VERSION ""

NS_ :

BS_:

BU_: BMS Third_Party_Device

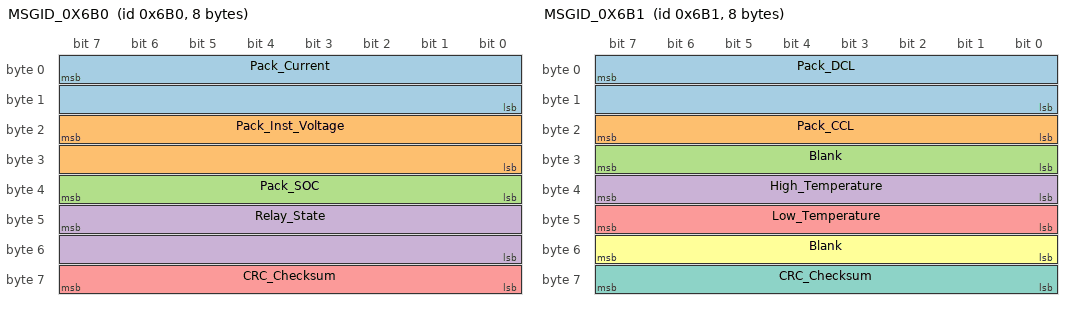
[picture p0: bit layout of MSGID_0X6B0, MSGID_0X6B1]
BO_ 1712 MSGID_0X6B0: 8 BMS
 SG_ Pack_Current : 7|16@0+ (0.1,0) [0|0] "Amps"  Third_Party_Device
 SG_ Pack_Inst_Voltage : 23|16@0+ (0.1,0) [0|0] "Volts"  Third_Party_Device
 SG_ Pack_SOC : 39|8@0+ (0.5,0) [0|0] "Percent"  Third_Party_Device
 SG_ Relay_State : 47|16@0+ (1.0,0) [0|0] ""  Third_Party_Device
 SG_ CRC_Checksum : 63|8@0+ (1.0,1720) [0|0] ""  Third_Party_Device

BO_ 1713 MSGID_0X6B1: 8 BMS
 SG_ Pack_DCL : 7|16@0+ (1.0,0) [0|0] "Amps"  Third_Party_Device
 SG_ Pack_CCL : 23|8@0+ (1.0,0) [0|0] "Amps"  Third_Party_Device
 SG_ Blank : 31|8@0+ (1.0,0) [0|0] ""  Third_Party_Device
 SG_ High_Temperature : 39|8@0+ (1.0,0) [0|0] "Celsius"  Third_Party_Device
 SG_ Low_Temperature : 47|8@0+ (1.0,0) [0|0] "Celsius"  Third_Party_Device
 SG_ Blank : 55|8@0+ (1.0,0) [0|0] ""  Third_Party_Device
 SG_ CRC_Checksum : 63|8@0+ (1.0,1721) [0|0] ""  Third_Party_Device

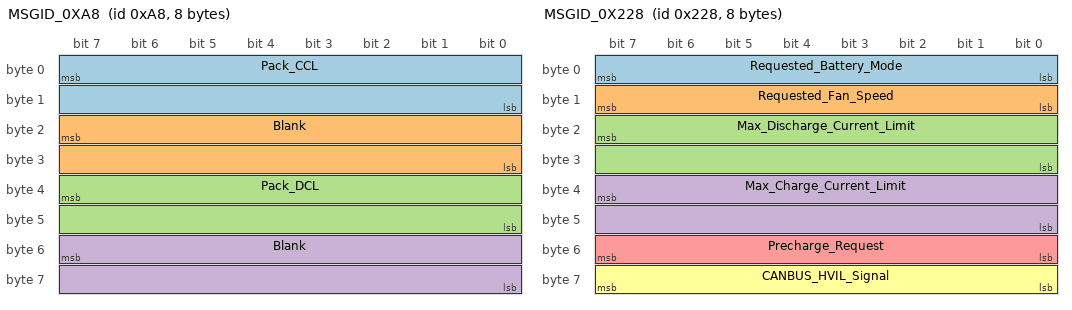
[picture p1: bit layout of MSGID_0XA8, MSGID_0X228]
BO_ 168 MSGID_0XA8: 8 BMS
 SG_ Pack_CCL : 7|16@0+ (0.1,0) [0|0] "Amps"  Third_Party_Device
 SG_ Blank : 23|16@0+ (1.0,0) [0|0] ""  Third_Party_Device
 SG_ Pack_DCL : 39|16@0+ (1.0,0) [0|0] "Amps"  Third_Party_Device
 SG_ Blank : 55|16@0+ (1.0,0) [0|0] ""  Third_Party_Device

BO_ 552 MSGID_0X228: 8 Third_Party_Device
 SG_ Requested_Battery_Mode : 7|8@0+ (1.0,0) [0|0] "#"  BMS
 SG_ Requested_Fan_Speed : 15|8@0+ (1.0,0) [0|0] "#"  BMS
 SG_ Max_Discharge_Current_Limit : 23|16@0+ (1.0,0) [0|0] "Amps"  BMS
 SG_ Max_Charge_Current_Limit : 39|16@0+ (1.0,0) [0|0] "Amps"  BMS
 SG_ Precharge_Request : 55|8@0+ (1.0,0) [0|0] "ON/OFF"  BMS
 SG_ CANBUS_HVIL_Signal : 63|8@0+ (1.0,0) [0|0] ""  BMS

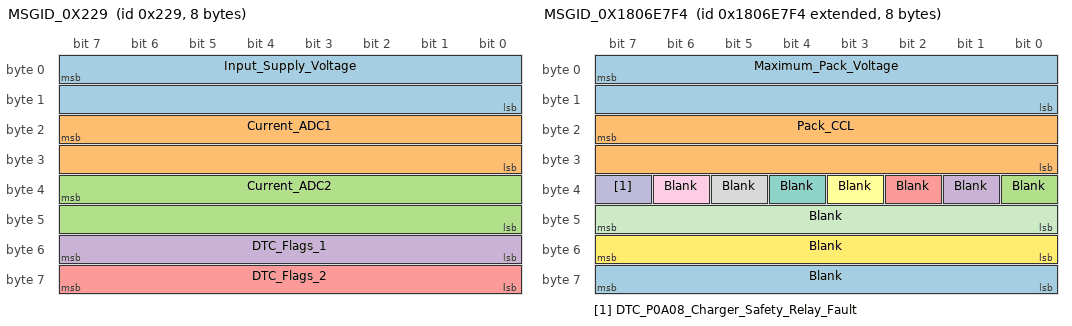
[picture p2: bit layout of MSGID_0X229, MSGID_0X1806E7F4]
BO_ 553 MSGID_0X229: 8 BMS
 SG_ Input_Supply_Voltage : 7|16@0+ (1.0,0) [0|0] "Volts"  Third_Party_Device
 SG_ Current_ADC1 : 23|16@0+ (1.0,0) [0|0] ""  Third_Party_Device
 SG_ Current_ADC2 : 39|16@0+ (1.0,0) [0|0] ""  Third_Party_Device
 SG_ DTC_Flags_1 : 55|8@0+ (1.0,0) [0|0] ""  Third_Party_Device
 SG_ DTC_Flags_2 : 63|8@0+ (1.0,0) [0|0] ""  Third_Party_Device

BO_ 2550589428 MSGID_0X1806E7F4: 8 BMS
 SG_ Maximum_Pack_Voltage : 7|16@0+ (0.1,0) [0|0] "Volts"  Third_Party_Device
 SG_ Pack_CCL : 23|16@0+ (0.1,0) [0|0] "Amps"  Third_Party_Device
 SG_ Blank : 32|1@1+ (1.0,0) [0|1] ""  Third_Party_Device
 SG_ Blank : 33|1@1+ (1.0,0) [0|1] ""  Third_Party_Device
 SG_ Blank : 34|1@1+ (1.0,0) [0|1] ""  Third_Party_Device
 SG_ Blank : 35|1@1+ (1.0,0) [0|1] ""  Third_Party_Device
 SG_ Blank : 36|1@1+ (1.0,0) [0|1] ""  Third_Party_Device
 SG_ Blank : 37|1@1+ (1.0,0) [0|1] ""  Third_Party_Device
 SG_ Blank : 38|1@1+ (1.0,0) [0|1] ""  Third_Party_Device
 SG_ DTC_P0A08_Charger_Safety_Relay_Fault : 39|1@1+ (1.0,0) [0|1] ""  Third_Party_Device
 SG_ Blank : 47|8@0+ (0.1,0) [0|0] ""  Third_Party_Device
 SG_ Blank : 55|8@0+ (1.0,0) [0|0] ""  Third_Party_Device
 SG_ Blank : 63|8@0+ (1.0,0) [0|0] ""  Third_Party_Device

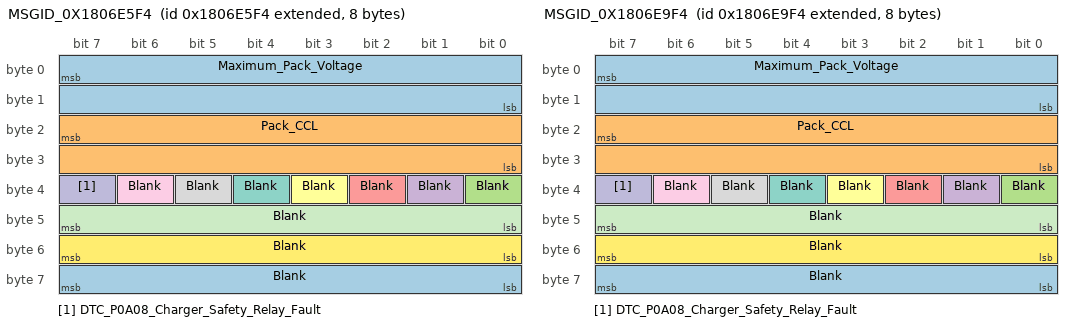
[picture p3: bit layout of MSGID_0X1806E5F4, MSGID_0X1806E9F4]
BO_ 2550588916 MSGID_0X1806E5F4: 8 BMS
 SG_ Maximum_Pack_Voltage : 7|16@0+ (0.1,0) [0|0] "Volts"  Third_Party_Device
 SG_ Pack_CCL : 23|16@0+ (0.1,0) [0|0] "Amps"  Third_Party_Device
 SG_ Blank : 32|1@1+ (1.0,0) [0|1] ""  Third_Party_Device
 SG_ Blank : 33|1@1+ (1.0,0) [0|1] ""  Third_Party_Device
 SG_ Blank : 34|1@1+ (1.0,0) [0|1] ""  Third_Party_Device
 SG_ Blank : 35|1@1+ (1.0,0) [0|1] ""  Third_Party_Device
 SG_ Blank : 36|1@1+ (1.0,0) [0|1] ""  Third_Party_Device
 SG_ Blank : 37|1@1+ (1.0,0) [0|1] ""  Third_Party_Device
 SG_ Blank : 38|1@1+ (1.0,0) [0|1] ""  Third_Party_Device
 SG_ DTC_P0A08_Charger_Safety_Relay_Fault : 39|1@1+ (1.0,0) [0|1] ""  Third_Party_Device
 SG_ Blank : 47|8@0+ (0.1,0) [0|0] ""  Third_Party_Device
 SG_ Blank : 55|8@0+ (1.0,0) [0|0] ""  Third_Party_Device
 SG_ Blank : 63|8@0+ (1.0,0) [0|0] ""  Third_Party_Device

BO_ 2550589940 MSGID_0X1806E9F4: 8 BMS
 SG_ Maximum_Pack_Voltage : 7|16@0+ (0.1,0) [0|0] "Volts"  Third_Party_Device
 SG_ Pack_CCL : 23|16@0+ (0.1,0) [0|0] "Amps"  Third_Party_Device
 SG_ Blank : 32|1@1+ (1.0,0) [0|1] ""  Third_Party_Device
 SG_ Blank : 33|1@1+ (1.0,0) [0|1] ""  Third_Party_Device
 SG_ Blank : 34|1@1+ (1.0,0) [0|1] ""  Third_Party_Device
 SG_ Blank : 35|1@1+ (1.0,0) [0|1] ""  Third_Party_Device
 SG_ Blank : 36|1@1+ (1.0,0) [0|1] ""  Third_Party_Device
 SG_ Blank : 37|1@1+ (1.0,0) [0|1] ""  Third_Party_Device
 SG_ Blank : 38|1@1+ (1.0,0) [0|1] ""  Third_Party_Device
 SG_ DTC_P0A08_Charger_Safety_Relay_Fault : 39|1@1+ (1.0,0) [0|1] ""  Third_Party_Device
 SG_ Blank : 47|8@0+ (1.0,0) [0|0] ""  Third_Party_Device
 SG_ Blank : 55|8@0+ (1.0,0) [0|0] ""  Third_Party_Device
 SG_ Blank : 63|8@0+ (1.0,0) [0|0] ""  Third_Party_Device

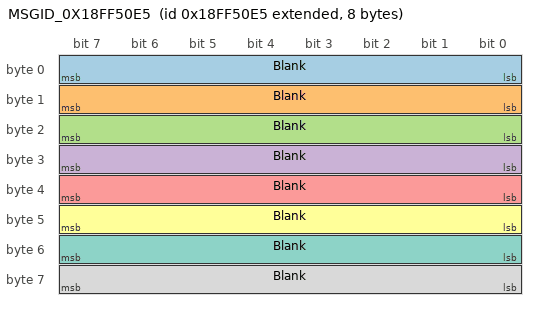
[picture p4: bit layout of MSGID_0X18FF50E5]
BO_ 2566869221 MSGID_0X18FF50E5: 8 Third_Party_Device
 SG_ Blank : 7|8@0+ (1.0,0) [0|0] ""  BMS
 SG_ Blank : 15|8@0+ (1.0,0) [0|0] ""  BMS
 SG_ Blank : 23|8@0+ (1.0,0) [0|0] ""  BMS
 SG_ Blank : 31|8@0+ (1.0,0) [0|0] ""  BMS
 SG_ Blank : 39|8@0+ (1.0,0) [0|0] ""  BMS
 SG_ Blank : 47|8@0+ (1.0,0) [0|0] ""  BMS
 SG_ Blank : 55|8@0+ (1.0,0) [0|0] ""  BMS
 SG_ Blank : 63|8@0+ (1.0,0) [0|0] ""  BMS

CM_ BO_ 1712 "This ID Transmits at 8 ms.";
CM_ BO_ 1713 "This ID Transmits at 104 ms.";
CM_ BO_ 168 "This ID Transmits at 104 ms.";
CM_ BO_ 553 "This ID Transmits at 104 ms.";
CM_ BO_ 2550589428 "This ID Transmits at 808 ms.";
CM_ BO_ 2550588916 "This ID Transmits at 808 ms.";
CM_ BO_ 2550589940 "This ID Transmits at 808 ms.";
